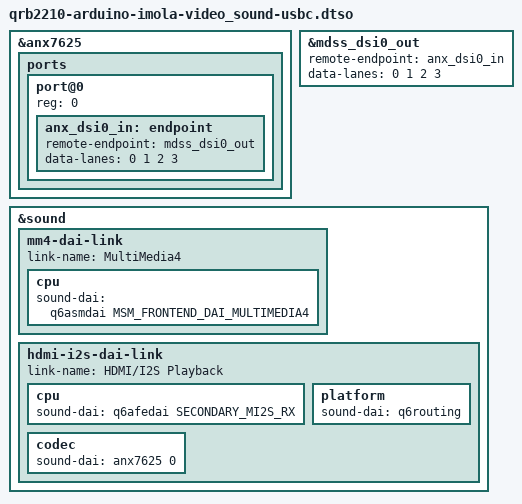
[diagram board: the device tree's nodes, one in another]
// SPDX-License-Identifier: (GPL-2.0+ OR BSD-3-Clause)
/*
 * Copyright (c) 2025, Arduino SA
 */

/dts-v1/;
/plugin/;

#include <dt-bindings/sound/qcom,q6asm.h>
#include <dt-bindings/sound/qcom,q6dsp-lpass-ports.h>

&anx7625 {
	ports {
		#address-cells = <1>;
		#size-cells = <0>;

		port@0 {
			reg = <0>;
			anx_dsi0_in: endpoint {
				remote-endpoint = <&mdss_dsi0_out>;
				data-lanes = <0 1 2 3>;
			};
		};
	};
};

&mdss_dsi0_out {
	remote-endpoint = <&anx_dsi0_in>;
	data-lanes = <0 1 2 3>;
};

&sound {
	mm4-dai-link {
		link-name = "MultiMedia4";

		cpu {
			sound-dai = <&q6asmdai MSM_FRONTEND_DAI_MULTIMEDIA4>;
		};
	};

	hdmi-i2s-dai-link {
		link-name = "HDMI/I2S Playback";

		cpu {
			sound-dai = <&q6afedai SECONDARY_MI2S_RX>;
		};

		platform {
			sound-dai = <&q6routing>;
		};

		codec {
			sound-dai = <&anx7625 0>;
		};
	};
};
